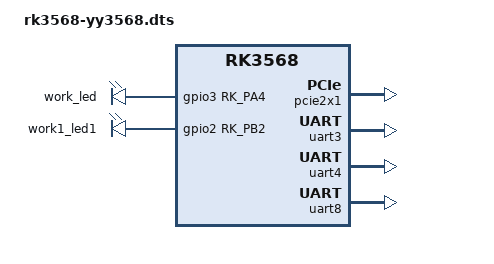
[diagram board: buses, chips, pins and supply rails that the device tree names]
// SPDX-License-Identifier: (GPL-2.0+ OR MIT)
/*
 * Copyright (c) 2020 Rockchip Electronics Co., Ltd.
 *
 */
#include "rk3568-evb1-ddr4-v10.dtsi"
#include "rk3568-linux.dtsi"
#include <dt-bindings/display/rockchip_vop.h>

#define WIFI_SWITCH 1        /* 1:wifi 0:sata*/
#define DISPLAY_SWITCH 2     /* 0:DSI0 1:DSI1 2:EDP*/


&pmu_io_domains {
	status = "okay";
	pmuio2-supply = <&vcc3v3_pmu>;
	vccio1-supply = <&vccio_acodec>;
	vccio3-supply = <&vccio_sd>;
	vccio4-supply = <&vcc_1v8>;
	vccio5-supply = <&vcc_3v3>;
	vccio6-supply = <&vcc_1v8>;
	vccio7-supply = <&vcc_3v3>;
};

#if WIFI_SWITCH

&pcie20m2_pins {
	rockchip,pins =
	/* pcie20_clkreqnm2 */
	<1 RK_PB0 4 &pcfg_pull_none>,
	/* pcie20_wakenm2 */
	<1 RK_PB1 4 &pcfg_pull_none>;
};

&pcie2x1 {
	status = "okay";
};
&sata2 {
        status = "disabled";
};
#else
&pcie2x1 {
	status = "disabled";
};
&sata2 {
        status = "okay";
};
#endif

&uart3{
    pinctrl-0 = <&uart3m1_xfer>;
    status = "okay";
};

&uart4{
    pinctrl-0 = <&uart4m1_xfer>;
    status = "okay";
};

&uart8{
        pinctrl-0 = <&uart8m0_xfer>;
    status = "okay";
};

&video_phy0 {
	status = "disabled";
};

&video_phy1 {
	status = "disabled";
};

&dsi0 {
	status = "disabled";
};

&dsi1 {
	status = "disabled";
};

#if DISPLAY_SWITCH == 0
#include "rk3568-vp1-mipi-dsi0-1024x768.dtsi"
#elif DISPLAY_SWITCH == 1
#include "rk3568-vp1-mipi-dsi1-1024x768.dtsi"
#else
#include "rk3568-vp1-edp-1080p.dtsi"
#endif

&vp0 {
	cursor-win-id = <ROCKCHIP_VOP2_CLUSTER0>;
};

&vp1 {
	cursor-win-id = <ROCKCHIP_VOP2_CLUSTER1>;
};

&leds {
	compatible = "gpio-leds";
	work_led: work {
		gpios = <&gpio3 RK_PA4 GPIO_ACTIVE_HIGH>;
		linux,default-trigger = "off";
	};

	work1_led1: work1{
		gpios = <&gpio2 RK_PB2 GPIO_ACTIVE_HIGH>;
		linux,default-trigger = "off";
	};
};
